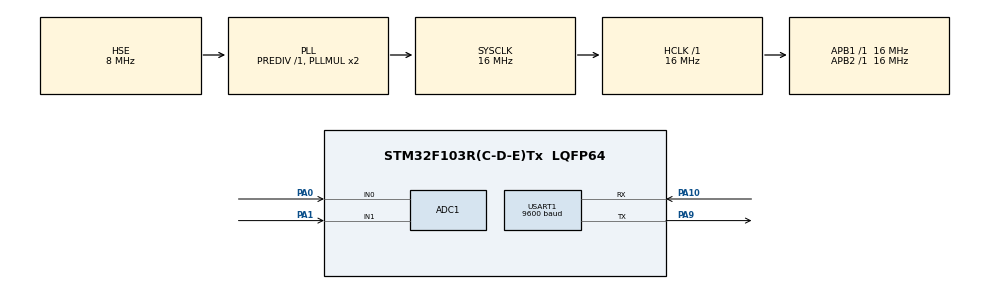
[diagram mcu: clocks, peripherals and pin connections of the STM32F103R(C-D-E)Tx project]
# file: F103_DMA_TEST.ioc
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ADC1.Channel-0\#ChannelRegularConversion=ADC_CHANNEL_0
ADC1.Channel-1\#ChannelRegularConversion=ADC_CHANNEL_1
ADC1.ContinuousConvMode=ENABLE
ADC1.NbrOfConversion=2
ADC1.NbrOfConversionFlag=1
ADC1.Rank-0\#ChannelRegularConversion=1
ADC1.Rank-1\#ChannelRegularConversion=2
ADC1.SamplingTime-0\#ChannelRegularConversion=ADC_SAMPLETIME_1CYCLE_5
ADC1.SamplingTime-1\#ChannelRegularConversion=ADC_SAMPLETIME_1CYCLE_5
ADC1.master=1
Dma.ADC1.0.Direction=DMA_PERIPH_TO_MEMORY
Dma.ADC1.0.Instance=DMA1_Channel1
Dma.ADC1.0.MemDataAlignment=DMA_MDATAALIGN_WORD
Dma.ADC1.0.MemInc=DMA_MINC_ENABLE
Dma.ADC1.0.Mode=DMA_NORMAL
Dma.ADC1.0.PeriphDataAlignment=DMA_PDATAALIGN_WORD
Dma.ADC1.0.PeriphInc=DMA_PINC_DISABLE
Dma.ADC1.0.Priority=DMA_PRIORITY_LOW
Dma.Request0=ADC1
Mcu.Family=STM32F1
Mcu.Name=STM32F103R(C-D-E)Tx
Mcu.Package=LQFP64
NVIC.DMA1_Channel1_IRQn=true\:0\:0\:false\:false\:true\:false\:true
NVIC.PriorityGroup=NVIC_PRIORITYGROUP_4
PA0-WKUP.Signal=ADCx_IN0
PA1.Signal=ADCx_IN1
PA10.Mode=Asynchronous
PA10.Signal=USART1_RX
PA9.Mode=Asynchronous
PA9.Signal=USART1_TX
PD0-OSC_IN.Mode=HSE-External-Oscillator
PD0-OSC_IN.Signal=RCC_OSC_IN
PD1-OSC_OUT.Mode=HSE-External-Oscillator
PD1-OSC_OUT.Signal=RCC_OSC_OUT
ProjectManager.HeapSize=0x200
ProjectManager.StackSize=0x400
ProjectManager.TargetToolchain=MDK-ARM V5.27
RCC.AHBFreq_Value=16000000
RCC.APB1Freq_Value=16000000
RCC.APB1TimFreq_Value=16000000
RCC.APB2Freq_Value=16000000
RCC.APB2TimFreq_Value=16000000
RCC.HCLKFreq_Value=16000000
RCC.PLLSourceVirtual=RCC_PLLSOURCE_HSE
RCC.SYSCLKFreq_VALUE=16000000
RCC.SYSCLKSource=RCC_SYSCLKSOURCE_PLLCLK
RCC.USBFreq_Value=16000000
SH.ADCx_IN0.0=ADC1_IN0,IN0
SH.ADCx_IN1.0=ADC1_IN1,IN1
USART1.BaudRate=9600
USART1.VirtualMode=VM_ASYNC
VP_SYS_VS_ND.Mode=No_Debug
board=custom

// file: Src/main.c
/* USER CODE BEGIN Header */
/**
  ******************************************************************************
  * @file           : main.c
  * @brief          : Main program body
  ******************************************************************************
  * @attention
  *
  * <h2><center>&copy; Copyright (c) 2020 STMicroelectronics.
  * All rights reserved.</center></h2>
  *
  * This software component is licensed by ST under BSD 3-Clause license,
  * the "License"; You may not use this file except in compliance with the
  * License. You may obtain a copy of the License at:
  *                        opensource.org/licenses/BSD-3-Clause
  *
  ******************************************************************************
  */
/* USER CODE END Header */

#include "main.h"
#include "adc.h"
#include "dma.h"
#include "usart.h"
#include "gpio.h"

/* USER CODE BEGIN Includes */
#include "stdio.h"
/* USER CODE END Includes */

void SystemClock_Config(void);

int main(void)
{
  /* USER CODE BEGIN 1 */
	uint32_t rx[10] = {0};
	int i ;
  /* USER CODE END 1 */

  /* MCU Configuration--------------------------------------------------------*/

  /* Reset of all peripherals, Initializes the Flash interface and the Systick. */
  HAL_Init();

  /* Configure the system clock */
  SystemClock_Config();

  /* Initialize all configured peripherals */
  MX_GPIO_Init();
  MX_DMA_Init();
  MX_ADC1_Init();
  MX_USART1_UART_Init();

  /* Infinite loop */
  /* USER CODE BEGIN WHILE */
  while (1)
  {
			HAL_ADC_Start_DMA(&hadc1,(uint32_t*)&rx,10);
		//if(hal_adc_
		HAL_Delay(1000);
		HAL_ADC_Stop_DMA(&hadc1);
		for(i=0;i<10;i++){
			printf("%2.3f\r\n",(rx[i]*1.0*3.3/4096));
		}

		HAL_Delay(2000);
    /* USER CODE END WHILE */

  }
}

void SystemClock_Config(void)
{
  RCC_OscInitTypeDef RCC_OscInitStruct = {0};
  RCC_ClkInitTypeDef RCC_ClkInitStruct = {0};
  RCC_PeriphCLKInitTypeDef PeriphClkInit = {0};

  /** Initializes the CPU, AHB and APB busses clocks
  */
  RCC_OscInitStruct.OscillatorType = RCC_OSCILLATORTYPE_HSE;
  RCC_OscInitStruct.HSEState = RCC_HSE_ON;
  RCC_OscInitStruct.HSEPredivValue = RCC_HSE_PREDIV_DIV1;
  RCC_OscInitStruct.HSIState = RCC_HSI_ON;
  RCC_OscInitStruct.PLL.PLLState = RCC_PLL_ON;
  RCC_OscInitStruct.PLL.PLLSource = RCC_PLLSOURCE_HSE;
  RCC_OscInitStruct.PLL.PLLMUL = RCC_PLL_MUL2;
  if (HAL_RCC_OscConfig(&RCC_OscInitStruct) != HAL_OK)
  {
    Error_Handler();
  }
  /** Initializes the CPU, AHB and APB busses clocks
  */
  RCC_ClkInitStruct.ClockType = RCC_CLOCKTYPE_HCLK|RCC_CLOCKTYPE_SYSCLK
                              |RCC_CLOCKTYPE_PCLK1|RCC_CLOCKTYPE_PCLK2;
  RCC_ClkInitStruct.SYSCLKSource = RCC_SYSCLKSOURCE_PLLCLK;
  RCC_ClkInitStruct.AHBCLKDivider = RCC_SYSCLK_DIV1;
  RCC_ClkInitStruct.APB1CLKDivider = RCC_HCLK_DIV1;
  RCC_ClkInitStruct.APB2CLKDivider = RCC_HCLK_DIV1;

  if (HAL_RCC_ClockConfig(&RCC_ClkInitStruct, FLASH_LATENCY_0) != HAL_OK)
  {
    Error_Handler();
  }
  PeriphClkInit.PeriphClockSelection = RCC_PERIPHCLK_ADC;
  PeriphClkInit.AdcClockSelection = RCC_ADCPCLK2_DIV2;
  if (HAL_RCCEx_PeriphCLKConfig(&PeriphClkInit) != HAL_OK)
  {
    Error_Handler();
  }
}

void Error_Handler(void)
{
}

/************************ (C) COPYRIGHT STMicroelectronics *****END OF FILE****/
